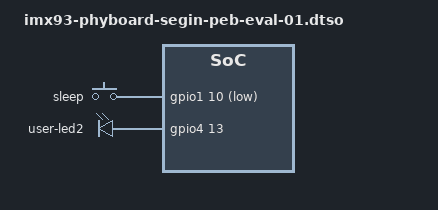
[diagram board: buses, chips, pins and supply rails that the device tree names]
// SPDX-License-Identifier: (GPL-2.0+ OR MIT)
/*
 * Copyright (C) 2025 PHYTEC Messtechnik GmbH
 * Author: Andrej Picej <andrej.picej@norik.com>
 */

/dts-v1/;
/plugin/;

#include <dt-bindings/gpio/gpio.h>
#include <dt-bindings/input/input.h>
#include "imx93-pinfunc.h"

&{/} {
	gpio-keys {
		compatible = "gpio-keys";
		pinctrl-names = "default";
		pinctrl-0 = <&pinctrl_gpio_keys>;

		button-s2 {
			label = "sleep";
			linux,code = <KEY_SLEEP>;
			gpios = <&gpio1 10 GPIO_ACTIVE_LOW>;
			wakeup-source;
		};
	};

	user-leds {
		compatible = "gpio-leds";
		pinctrl-names = "default";
		pinctrl-0 = <&pinctrl_user_leds>;

		user-led2 {
			gpios = <&gpio4 13 GPIO_ACTIVE_HIGH>;
			default-state = "on";
		};
	};
};

&iomuxc {
	pinctrl_gpio_keys: gpiokeysgrp {
		fsl,pins = <
			MX93_PAD_PDM_BIT_STREAM1__GPIO1_IO10	0x31e
		>;
	};

	pinctrl_user_leds: userledsgrp {
		fsl,pins = <
			MX93_PAD_ENET1_RD3__GPIO4_IO13		0x31e
		>;
	};
};
